# cslr_etb register map
Vendor: Texas Instruments
Peripheral module from a debugger description file (folder c6472).
Registers are 32-bit, access not given, reset 0x0 unless marked. A register's access mark holds for its fields unless they carry their own. Offsets are as the file gives them; lines under a group give offsets from that group; [hi:lo] are bit positions; {n}, {i} and the like mark numbered series; 'fields as' and 'values as' point back to an identical list; <NAME> marks a mode.

## ETB — External Trace Buffer
0x04 RDP ro reset 0x200 — RAM Depth Register
  [31:0] RDP — RAM Depth
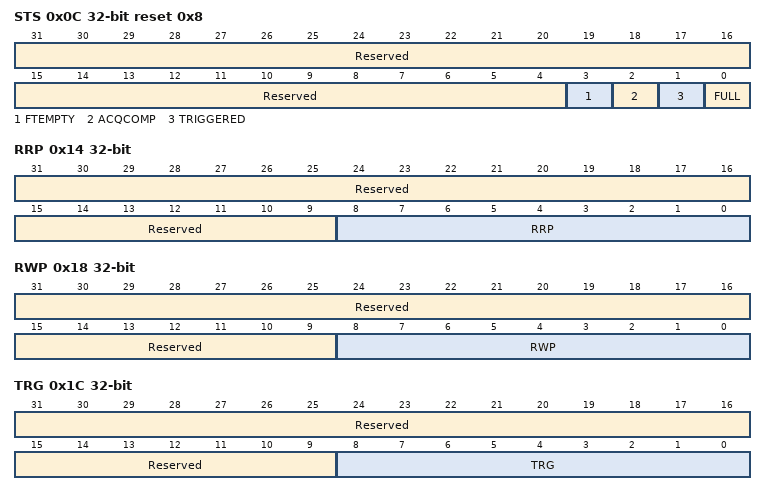
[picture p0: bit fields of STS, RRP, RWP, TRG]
0x0C STS reset 0x8 — Status Register
  [31:4] Reserved — (access N)
  [3] FTEMPTY ro — Formatterpipeline empty, All data stored to RAM
  [2] ACQCOMP ro — Acquisition complete
  [1] TRIGGERED ro — Trigger bit set when a trigger has been observed
  [0] FULL ro — RAM Full (RAM write pointer has wrapped around)
0x10 RRD ro — RAM Read Data
  [31:0] RRD — RAM read Data
0x14 RRP — RAM Read Pointer register
  [31:9] Reserved — (access N)
  [8:0] RRP rw — RAM pointer register
0x18 RWP — RAM Write Pointer register
  [31:9] Reserved — (access N)
  [8:0] RWP rw — RAM write pointer register
0x1C TRG — Trigger Counter Register
  [31:9] Reserved — (access N)
  [8:0] TRG rw — Trigger counter register
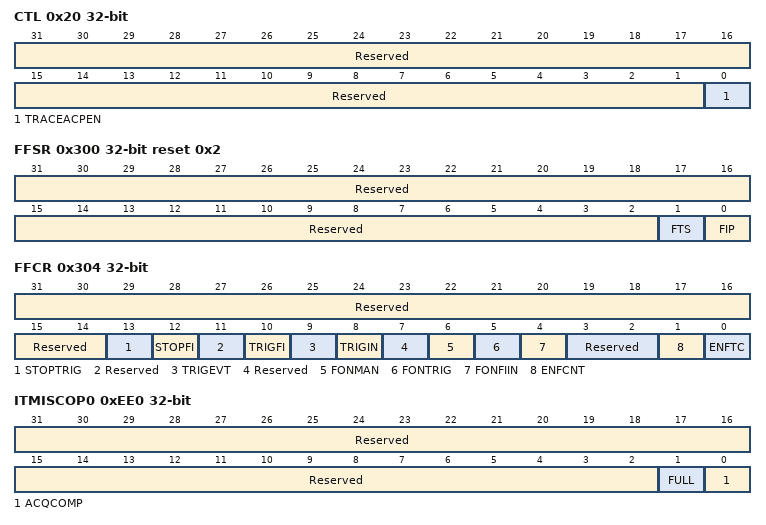
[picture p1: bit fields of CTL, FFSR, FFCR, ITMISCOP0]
0x20 CTL — Control Register
  [31:1] Reserved — (access N)
  [0] TRACEACPEN rw — Trace Capture Enable/Disable
    0=DISABLE; 1=ENABLE
0x24 RWD rw — RAM write Data Register
  [31:0] RWD — Data written to ETB trace RAM
0x300 FFSR reset 0x2 — Formatter and flush status register
  [31:2] Reserved — (access N)
  [1] FTS ro — Formatter stopped
  [0] FIP ro — Flush in progress
0x304 FFCR — Formatter and flush control register
  [31:14] Reserved — (access N)
  [13] STOPTRIG rw — Stop the formatter once a trigger event has been observed
  [12] STOPFI rw — Stop the formatter once a flush has completed
  [11] Reserved — (access N)
  [10] TRIGFI rw — Indicate a trigger on flush completion
  [9] TRIGEVT rw — Indicate a trigger on Trigger event
  [8] TRIGIN rw — Indicate a trigger on TRIGIN being asserted
  [7] Reserved — (access N)
  [6] FONMAN rw — Manually generate a flush of the system
  [5] FONTRIG rw — Generate Flush using Trigger event
  [4] FONFIIN rw — Generate Flush using FLUSHIN interface
  [3:2] Reserved — (access N)
  [1] ENFCNT rw — Continuous Formatting
  [0] ENFTC rw — Enable Formatting
0xEE0 ITMISCOP0 — Integration register
  [31:2] Reserved — (access N)
  [1] FULL wo — Set the value of FULL
  [0] ACQCOMP wo — Set the value of ACQCOMP
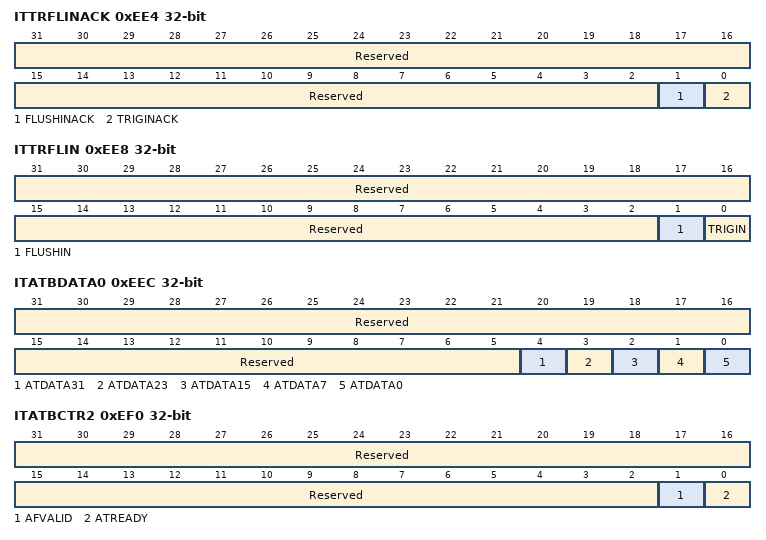
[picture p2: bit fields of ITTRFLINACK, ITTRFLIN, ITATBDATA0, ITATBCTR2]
0xEE4 ITTRFLINACK — Integration register
  [31:2] Reserved — (access N)
  [1] FLUSHINACK wo — Set the value of FLUSHACK
  [0] TRIGINACK wo — Set the value of TRIGACK
0xEE8 ITTRFLIN — Integration register
  [31:2] Reserved — (access N)
  [1] FLUSHIN ro — Read the value of FLUSHIN
  [0] TRIGIN ro — Read the value of TRIGIN
0xEEC ITATBDATA0 — Integration register
  [31:5] Reserved — (access N)
  [4] ATDATA31 ro — Read value of ATDATA[31]
  [3] ATDATA23 ro — Read value of ATDATA[23]
  [2] ATDATA15 ro — Read value of ATDATA[15]
  [1] ATDATA7 ro — Read value of ATDATA[7]
  [0] ATDATA0 ro — Read value of ATDATA[0]
0xEF0 ITATBCTR2 — Integration register
  [31:2] Reserved — (access N)
  [1] AFVALID wo — Set the value of ATVALID
  [0] ATREADY wo — Set the value of ATREADY
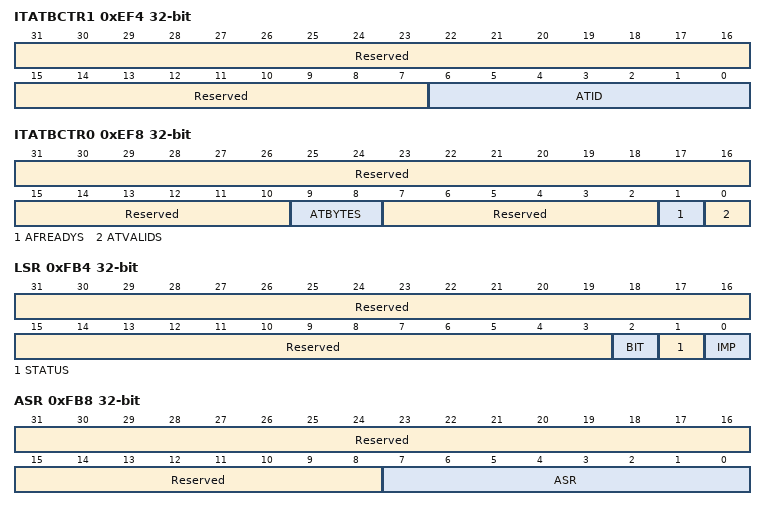
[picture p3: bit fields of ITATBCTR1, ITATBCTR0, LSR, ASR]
0xEF4 ITATBCTR1 — Integration register
  [31:7] Reserved — (access N)
  [6:0] ATID ro — Read the value of ATID
0xEF8 ITATBCTR0 — Integration register
  [31:10] Reserved — (access N)
  [9:8] ATBYTES ro — Read the value of ATBYTES
  [7:2] Reserved — (access N)
  [1] AFREADYS ro — Read the value of ATREADYS
  [0] ATVALIDS ro — Read the value of ATVALIDS
0xFB0 LAR wo — Authentication Status register
  [31:0] LAR — Reports security level
0xFB4 LSR — Authentication Status register
  [31:3] Reserved — (access N)
  [2] BIT — Lock register length
    0=32BIT (Device implements a 32-bit lock register.); 1=8BIT (Device implements an 8-bit lock register.)
  [1] STATUS — Lock register
    0=LOCKED (Device write access is locked.); 1=UNLOCKED (Device write access has been granted.)
  [0] IMP ro — Lock control mechanism
    0=DISABLE (Lock mechanism is not implemented.); 1=ENABLE (Lock mechanism is implemented.)
0xFB8 ASR — Authentication Status register
  [31:8] Reserved — (access N)
  [7:0] ASR ro — Reports security level
0xFC8 DID ro — Device ID
  [31:0] ID
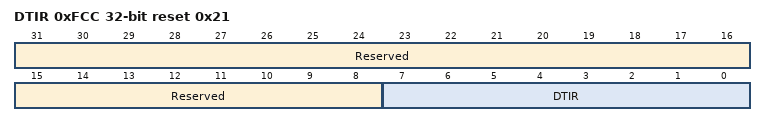
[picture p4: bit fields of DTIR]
0xFCC DTIR reset 0x21 — Device Type Identification Register
  [31:8] Reserved — (access N)
  [7:0] DTIR ro — Indicates it is a trace sink
